# soc_aon_secure register map
Vendor: Texas Instruments
Registers are 32-bit, access per field, reset 0x0 unless marked. A register's access mark holds for its fields unless they carry their own. Offsets are as the file gives them; [hi:lo] are bit positions; {n}, {i} and the like mark numbered series; 'fields as' and 'values as' point back to an identical list.

## soc_aon_secure (part 3 of 3)
0x20D0 osprey_soc_aon_fuse_line1 ro — Fuse Line 1. Actual fuse line is 33.
  [31:0] UNQ31TO0 — Unique Device Identification [31:0]
0x20D4 osprey_soc_aon_fuse_line2 ro — Fuse Line 2. Actual fuse line is 34.
  [31:0] UNQ63TO32 — Unique Device Identification [63:32]
{0x20CC+4i} secgv_osprey_soc_aon_fuse_line{i} ro (i=3..6) — Fuse Line {i}. Actual fuse line is {i+32}.
  [31:0] UNQS{32i-65}TO{32i-96} — Unique Device Secret [{32i-65}:{32i-96}]
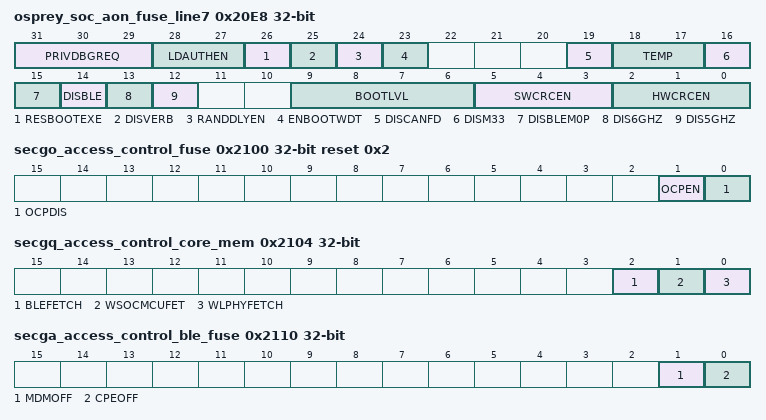
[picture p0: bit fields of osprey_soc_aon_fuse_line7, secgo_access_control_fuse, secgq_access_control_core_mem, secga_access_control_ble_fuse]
0x20E8 osprey_soc_aon_fuse_line7 ro — Fuse Line 7. Actual fuse line is 39.
  [31:29] PRIVDBGREQ — Enforce TI privilege Debug Request (Relevant in AT TEST privilege only used by SW) 0 - Disable other (1-7) - Enable (When SW check these bits: if equal to '0' bypass otherwise check.)
  [28:27] LDAUTHEN — RAM Bootloader authentication enable: 00 - Disable Other- Enable
  [26] RESBOOTEXE — Resume boot in non-normal boot flows where the boot cannot progress (e.g. when assets are hidden). For example, in forced supply in operational or deployed life cycles, 1st bday/at test (normal) life cycles, etc. 0 - Halt boot execution as early as possible 1 - Resume/Continue boot execution This bit is ignored when the device can run the boot flow normally (e.g. deployed life cycle with default SOP).
  [25] DISVERB — Disable Verbose Mode 0 - Verbose Mode (Enable) - Full Logger 1 - Normal Mode (Disable)
  [24] RANDDLYEN — Random Delay Enable: 0 - Disable 1 - Enable
  [23] ENBOOTWDT — Enable watchdog timer for protecting boot: (This enable M33 watchdog second threshold to reset device when asserted). 0 - Disable Boot Watchdog 1 - Enable Boot Watchdog
  [19] DISCANFD — Disable CAN FD - to eliminate the need to pay royalties 0 - Enable 1 - Disable (In probe we can program '0' (which practically means not programming) to achieve continuous programming it of all shifted rows) HCANEN (Enable/Disable the CAN IP) - Determined according to paper spin HCANRAMEN(Enable disable access to CAN memory) - Determined according to paper spin. HCANFDEN - Disable/Enable CAN. Determined according to eFuse bit (this bit)
  [18:17] TEMP — Supported Temperature 00 - 85degC 01 - 105degC 10 - 125degC 11 - Reserved
  [16] DISM33 — Disable M33 0 - Enable 1 - Disable (In probe we can program '0' (which practically means not programming) to achieve continuous programming it of all shifted rows)
  [15] DISBLEM0P — Disable BLE M0+ (RFC_CPE_CLKEN ) 0 - Enable 1 - Disable (In probe we can program '0' (which practically means not programming) to achieve continuous programming it of all shifted rows)
  [14] DISBLE — Disable BLE (RFC_MDM_CLKEN) 0 - Enable 1 - Disable (In probe we can program '0' (which practically means not programming) to achieve continuous programming it of all shifted rows)
  [13] DIS6GHZ — Disable 6GHz 0 - Enable 1 - Disable (In probe we can program '0' (which practically means not programming) to achieve continuous programming it of all shifted rows)
  [12] DIS5GHZ — Disable 5GHz 0 - Enable 1 - Disable (In probe we can program '0' (which practically means not programming) to achieve continuous programming it of all shifted rows)
  [9:6] BOOTLVL — Determine which part of the boot ROM bypass options for risk mitigation Level0 - Do not bypass anything Level1- Ignore Error Level2 - TI ROM bypass Level3 - Minimize access to HW. Do min mandatory. 0b0110 - Level3 0b1010 - Level 2 0b0101 - Level 1 All the rest - Level 0
  [5:3] SWCRCEN — SW CRC check Enable/Disable: 0 - Disable Other (1-7) - Enable (When SW check these bits: if equal to '0' do not check otherwise check.)
  [2:0] HWCRCEN — HW CRC check Enable/Disable: 0 - Disable other (1-7) - Enable (When HW check these bits: if equal to '0' do not check otherwise check.)
0x20EC osprey_soc_aon_fuse_line8 ro — Fuse Line 8. Actual fuse line is 40.
  [31:0] HWCRCVAL — HW CRC Check for all shifted rows. XORs operation with 0x04C11DB7 CRC32 polynomial engine. Init value = 0
0x2100 secgo_access_control_fuse reset 0x2 — Fuse Access Control. disconnect fuse from OCP access. locked with fuse_ocp_disable_lock.
  [1] OCPEN rw — OTP FROM , when jtag is 1 the i/f is jtag regardless of ocp_en to enable OCP need to write this bit to 1 and jtag to 0 '1' by default. optional - write once to '0'.
  [0] OCPDIS rw — Disconnect FUSE FARM and OTP OCP access, should be configured once as locked on boot done
0x2104 secgq_access_control_core_mem — CORE Memory Access Control CORE CPU: Allow M3 Fetch From non-owned memory Allow WiFi M0+ Fetch From non-owned memory Allow BLE M0+ Fetch From non-owned memory
  [2] BLEFETCH rw — Allow BLE M0+ Fetch From non-owned memory
  [1] WSOCMCUFET rw — Allow M3 Fetch From non-owned memory
  [0] WLPHYFETCH rw — Allow WiFi M0+ Fetch From non-owned memory
0x2108 secga_access_control_core_gp reset 0x1 — Access Control - Core Global Port Enable
  [0] ALLOW rw — Allow CORE global port. when enabled allow access to core (based on firewall configuration), must stay enabled to allow host access to Nub (sdio) and locked on soc_boot_done
0x210C secga_access_control_memss_gp reset 0x1 — MEMSS Global Port Access Control. Allow access to entire memss through memss global port.
  [0] ALLOW rw — Access is allowed to both M33 & M3 during privilege boot and changed to M3 only (fixed firewall) after boot (controlled by soc_boot_done)
0x2110 secga_access_control_ble_fuse — BLE Fuse Access Control. Disable BLE modem and CPE clock - based on indication bits on fuse
  [1] MDMOFF rw — Disable the BLE MDM clock , should be configured based on fuse pare spin
  [0] CPEOFF rw — This control disable the clk to the CPE clk gate. should be disabled in WIFI only paper spin (based on fuse)
0x2118 secgc_elevated_mode — not in use. can be use as spare
  [0] BIT rw — spare bit
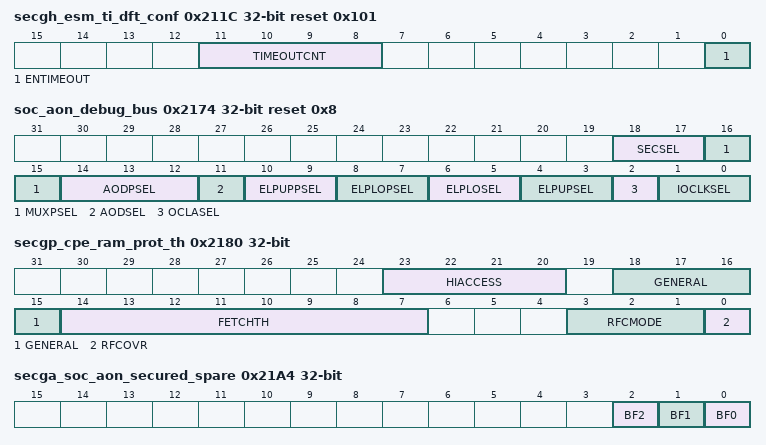
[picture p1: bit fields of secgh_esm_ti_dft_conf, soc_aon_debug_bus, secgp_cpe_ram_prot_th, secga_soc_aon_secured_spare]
0x211C secgh_esm_ti_dft_conf reset 0x101 — ESM4 Configuration- TI DFT Enable Sequence Monitor. Enable timeout mechanism and timeout counter value.
  [11:8] TIMEOUTCNT rw — This field sets the timeout value. time resolution equals to 16us. while: value 0 representing 16us value 1 - 2*16us value 2 - 3*16us and so on. value 15 is not supported.
  [0] ENTIMEOUT rw — This field enables timeout mechanism for ESM.
0x2120 ti_dft_en1 — ESM4 Enable Number 1.
  [0] EN1 wo — This field is the 1st enable for the ESM. Type: Write-Clear
0x2124 ti_dft_en2 — ESM4 Enable Number 2.
  [0] EN2 wo — This field is the 2nd enable for the ESM. Type: Write-Clear
0x2128 ti_dft_en3 — ESM4 Enable Number 3.
  [0] EN4 wo — This field is the 3rd enable for the ESM. Type: Write-Clear
0x212C ti_dft_en4 — ESM4 Enable Number 4.
  [0] EN4 wo — This field is the 4th enable for the ESM. Type: Write-Clear
0x2130 ti_dft_en5 — ESM4 Enable Number 5.
  [0] EN5 wo — This field is the 5th enable for the ESM. Type: Write-Clear
0x2140 secgb_socaon_access_protection access not given — This register is locking the CORE related security bits , should be written in boot and on elevated mode exit: [COREMEMCTL], [CRAMPROT1.FETCHTH], [DRAMPROT1.FETCHTH], [MEMPROT.MEMLOCK], [ROMJUMPCTL.DIS], [DRAMCTL.ERASEASST], [VTORCFG.INIT], [CPEPROT1.RFCOVR], [CPEPROT1.RFCMODE], [CPEPROT1.FETCHTH], [PHYPROT1.FETCHTH]
  [16] MEMLOCK — Locking the configurations on mem prot
0x2144 secgq_vtor — WSOC MCU VTOR CONFIGURATION. this is the jump address during boot (default is 0 - Rom) and after boot done - as POR this should be configured to CRAM start during boot of ROM. in boot done command the MCU will jump to this address
  [31:7] INIT rw — VTOR Init register
0x2148 secgc_mcu_rom_jumpdis — MCU ROM Jump Disable. Prevents the use of the VTOR function , by default it is off.
  [0] DIS rw — 0 - CTX icode bus jumps from 0x0/0x04 to vtor/vtor+4. 1 - Do not jump.
0x214C secgp_mcu_cram_prot_th — Execution RAM (CRAM) - Threshold register
  [15:7] WRTH rw — Below this CRAM Threshold register - Fetch/read only after 'mem_cram_write_disable_pulse'. Write is allowed above this threshold regardless to S/W setting the [CRAMPROT0.WRDIS]. Resolution is 1KB: (1- 1KB, 2 - 2KB, ..., 511 - 511KB). Effectively we have 384KB of Code-RAM
0x2150 mcu_cram_prot — Execution RAM (CRAM) - Protect from write
  [0] WRDIS wo — Write Once MMR protection - Do not allow writing to CRAM (below a threshold) after this MMR is set. S/W pulse (WRCL) that sets an H/W F.F - cannot be cleared by S/W.
0x2154 secgp_mcu_dram_prot_th — Execution RAM (CRAM) - Threshold register
  [14:7] FETCHTH rw — Below this DRAM Threshold register - read/write only (never-execute-region) after 'mem_dram_fetch_disable_pulse'. Fetch is allowed above this threshold regardless to S/W setting the [DRAMPROT0.FETCHDIS]. Resolution is 1KB: (1- 1KB, 2 - 2KB, ..., 255 - 255KB). Effectively we have 144KB of Data-RAM. [Cortex fetch from 61xx_xxxx (executable region) instead of 45xx_xxxx and the address is automatically (MCUSS H/W) remapped to 45xx_xxxx]
0x2158 mcu_dram_prot reset 0x200 (reset mask 0xFFFFFFFE) — Data RAM (DRAM) - Protect from fetch
  [0] FETCHDIS wo — Write Once MMR protection - Do not allow fetching from DRAM (below a threshold) after this MMR is set. S/W pulse (WRCL) that sets an H/W F.F - cannot be cleared by S/W.
0x2160 security_strong_pattern ro — Security Strong Pattern. the 24 bit pattern that is burn on the fuse to qualify the fuse data against possible attack
  [23:0] PAT — 24 bit pattern from fuse
0x2164 secgv_uds0 ro — Unique Device Secret. 31-0
  [31:0] _31TO0 — bits 31-0
{0x2164+4i} secgv_uds{i} ro (i=1..3) — Unique Device Secret. {32i+31}-{32i}
  [31:0] _{32i+31}TO{32i} — Bits {32i+31}-{32i}
0x2174 soc_aon_debug_bus reset 0x8 — SOC_AON Debug Bus. This register sets the debug over sleep and IOMUX debug bus selection
  [18:17] SECSEL rw — Security Debug Selector. selects soc aon debug bus
  [16:15] MUXPSEL rw — Debug Mux Port Selector. Chooses debug mux port '00' - prcm/elp '01' - soc aod '10' - ocla
  [14:12] AODPSEL rw — SOC AOD Port Selector. Chooses soc aod port '000' - host_aon_tp1 '001' - host_aon_tp2 '010' - io mux tp1 '011' - io mux tp2 '100' - debug aon tp1 '101' - debug aon tp2 '110' - soc aon tp1 '111' - rtc_tp1
  [11] AODSEL rw — SOC AOD Upper/Lower Selector. selects upper or lower 16 bits out of the soc aod bus of 32 '1' - 16 MSBs '0' - 16 LSBs
  [10:9] ELPUPPSEL rw — PRCM ELP Upper Port Selector. Chooses upper byte port '00' - prcm tp1 '01' - prcm tp2 '10' - elp tp1 '11' - elp tp2
  [8:7] ELPLOPSEL rw — PRCM ELP Lower Port Selector. Chooses lower byte port '00' - prcm tp1 '01' - prcm tp2 '10' - elp tp1 '11' - elp tp2
  [6:5] ELPLOSEL rw — PRCM ELP Lower Byte Selector. Chooses lower byte out of prcm elp 32 bit '00' - [7:0] '01' - [15:8] '10' - [23:16] '11' - [31:24]
  [4:3] ELPUPSEL rw — PRCM ELP Upper Byte Selector. Chooses upper byte out of prcm elp 32 bit '00' - [7:0] '01' - [15:8] '10' - [23:16] '11' - [31:24]
  [2] OCLASEL rw — OCLA bus upper/lower selector. selects upper or lower 16 bits out of the ocla bus of 32 '1' - 16 MSBs '0' - 16 LSBs
  [1:0] IOCLKSEL rw — selects the clock source for iomux debug clk 0 :SCLK 1: SOC CLK (40) 2: CORE M3 CLK (80)
0x217C debugss_jtagusercode rw — DEBUGSS JTAG User Code. This 32 bit register can be read through JTAG , and reflected on CFG-AP
  [31:0] JTAGUSER — This 32 bit register can be read through JTAG , and reflected on CFG-AP
0x2180 secgp_cpe_ram_prot_th reset not defined — Execution RAM (CRAM) - Threshold register
  [23:20] HIACCESS rw — Define the CPE (BLE CM0+) most high address space access allowed (should be configured according to MEM-SS mode). Value granularity is 16K, So for the default allocation of 64k it set to 3. (value 0 is for the lower 16k, value 15 is for 256k)
  [18:15] GENERAL rw — Bit 0 is force clk en for all BLE sub clocks . this is enabled on default for safety reasons on boot. this bit should be cleared by SW during boot and then internal IP clock manager takes control
  [14:7] FETCHTH rw — Above this BLE CPE Threshold register - read/write only (never-execute-region) after 'mem_dram_fetch_disable_pulse'. Fetch is allowed below this threshold regardless to S/W setting the [CPEPROT0.FETCHDIS]. Resolution is 1KB: (1- 1KB, 2 - 2KB, ..., 255 - 255KB). MSBit not in use (MSBit is reserved bit).
  [3:1] RFCMODE rw — RFC Confidential Mode.
  [0] RFCOVR rw — RFC Confidential Over.
0x2184 cpe_ram_prot reset 0x200 (reset mask 0xFFFFFFFE) — CPE Data RAM (DRAM) - Protect from fetch
  [0] FETCHDIS wo — Write Once MMR protection - Do not allow fetching from DRAM (above a threshold) after this MMR is set. S/W pulse (WRCL) that sets an H/W F.F - cannot be cleared by S/W.
0x2188 security_fuse_shift_crc ro — Security Fuse Shift CRC Calc result on fuse chain
  [31:0] CRCCALC — Calc CRC result of fuse chain - this include the CRC result crunching a s well, so expected / correct result would be 0.
0x218C security_hide_rom_assets — Security Hide Rom Assets. SW control to hide ROM assets, written once
  [0] HIDEASSETS wo — ROM is Hidden in case ATTEST or Error or if SOP=FS, during operational otherwise, during either Operational or ATTEST Privilege (except during privilege or elevated in which This MMR applies hide) Type: Write-Clear.
0x2190 security_hide_uds_assets — Security Hide UDS Assets. SW control to hide UDS assets, written once
  [0] HIDEASSETS wo — UDS is Hidden in case ATTEST or Error or.. during ATTEST-Privilege or Operational-and-not-in-force-supply-SOPs (except during soc privilege in which this MMR applies the hide) Type: Write-Clear.
0x2198 secgp_wlphy_ram_prot_th — WLPHY RAM memory protection - Threshold register
  [14:7] FETCHTH rw — Above this WLPHY Threshold register - read/write only (never-execute-region) after 'mem_wlphy_fetch_disable_pulse'. Fetch is allowed below this threshold regardless to S/W setting the [PHYPROT0.FETCHDIS]. Resolution is 1KB: (1- 1KB, 2 - 2KB, ..., 255 - 255KB). MSBit not in use. (MSBit is reserved bit)
0x219C wlphy_ram_prot reset 0x200 (reset mask 0xFFFFFFFE) — WLPHY RAM - Protect from fetch
  [0] FETCHDIS wo — Write Once MMR protection - Do not allow fetching from WLPHY RAM (above a threshold) after this MMR is set. S/W pulse (WRCL) that sets an H/W F.F - cannot be cleared by S/W.
0x21A0 esm_graceful_disable reset 0x200 (reset mask 0xFFFFFFFE) — ESMs Graceful Disable. Setting this bit - moving all ESM's from IDLE state to disabled state and cannot be configured until the next AON reset. notice this can be set only in IDLE mode - prior to other ESM configurations (i,e if ESM state is VIOLATED or DONE it will remain there)
  [0] DIS wo — Setting this bit - moving all ESM's from IDLE state to disabled state and cannot be configured until the next AON reset. notice this can be set only in IDLE mode - prior to other ESM configurations (i,e if ESM state is VIOLATED or DONE it will remain there)
0x21A4 secga_soc_aon_secured_spare — Spare bits , locked on boot
  [2] BF2 rw — Spare2 locked on boot done
  [1] BF1 rw — Spare1 locked on boot done
  [0] BF0 rw — Spare0 locked on boot done
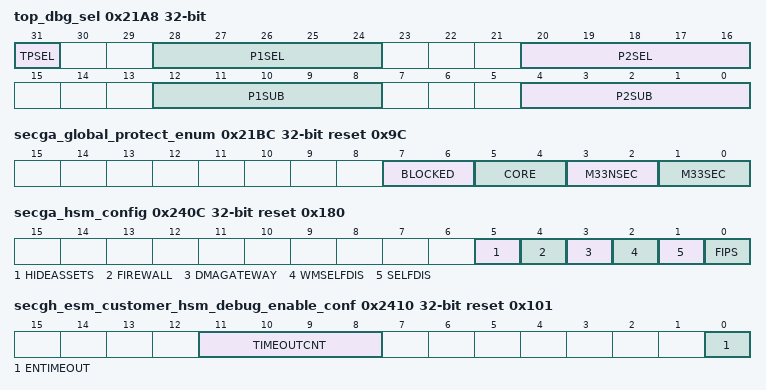
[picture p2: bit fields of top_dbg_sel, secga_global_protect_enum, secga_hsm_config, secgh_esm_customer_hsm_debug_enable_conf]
0x21A8 top_dbg_sel — Top Debug Selectors. This register selects debug ports from Top debug to OCLA. INTERNAL NOTE: [Confluence][https://confluence.itg.ti.com/display/WNG/Osprey+MDB+PG1.0+-+OCLA+integration+Spec] [LINUX- OSPREYMDB - MDBPG10C3V2 Branch][toplevel/wsoc/doc/wsoc.xls]
  [31] TPSEL rw — TP1/TP2 Selector. This field is used for Peripheral TP that have two 32bits TP (mode #3) e.g. SDIO_PHY, SDIO_FN1 In this case TP include 64 bits but we can expose only 32bits So we need this MMR field to select either TP1 or TP2 In this case this 16LSB(15:0) bit are connected to TP1 and 16MSB(31:16) to TP2 0 - Select IP TP1 1 - Select IP TP2 Example: TP1 = mem_ocla_tp1_tp2_sel ? IP_TP2[15: 0] : IP_TP1[15: 0] ; TP2 = mem_ocla_tp1_tp2_sel ? IP_TP2[31:16] : IP_TP1[31:16] ;
  [28:24] P1SEL rw — Port Set 1 - IP Selector. Selects the IP. INTERNAL NOTE- 2.2.4 SOC (TOP) [Confluence][https://confluence.itg.ti.com/display/WNG/Osprey+MDB+PG1.0+-+OCLA+integration+Spec]
  [20:16] P2SEL rw — Port Set 2 - IP Selector. Selects the IP. INTERNAL NOTE- 2.2.4 SOC (TOP) [Confluence][https://confluence.itg.ti.com/display/WNG/Osprey+MDB+PG1.0+-+OCLA+integration+Spec]
  [12:8] P1SUB rw — Port Set 1 - Submodule Selector. Selects the Submodule from the IP. INTERNAL NOTE- [LINUX- OSPREYMDB - MDBPG10C3V2 Branch][toplevel/wsoc/doc/wsoc.xls]
  [4:0] P2SUB rw — Port Set 2 - Submodule Selector. Selects the Submodule from the IP. INTERNAL NOTE- [LINUX- OSPREYMDB - MDBPG10C3V2 Branch][toplevel/wsoc/doc/wsoc.xls]
0x21BC secga_global_protect_enum reset 0x9C — Global Protect Enumeration. define of security group: [1:0] - M33 Secure [3:2] - M33 Non Secured [5:4] - Core [6:7] - Blocked
  [7:6] BLOCKED rw — BLOCKED Enumeration.
  [5:4] CORE rw — Core (M3) Enumeration.
  [3:2] M33NSEC rw — M33 Non-Secured Enumeration.
  [1:0] M33SEC rw — M33 Secured Enumeration.
{0x2370+0xC*i} doorbell{i}_m1_clr (i=0..7) — Doorbell {i} M3 Clear Register
  [0] CLR wo — M3 to clear the IRQ after handled the massage from M33. type : Write-Clear
0x2374 doorbell0_m1_pulse — Doorbell 0 M3 Set Register
  [0] IRQ wo — M3 to generate IRQ towards M33 after writing the message. type: Write-Clear
{0x2378+0xC*i} doorbell{i}_m1_lockbit (i=0..7) — Doorbell {i} M3 Lock Bit
  [1:0] LOCKBIT rw — Lock Bit. S/w attempt to lock upon read. if lock obtained, value set to 1 by h/w. M33 always looses to M3 Reading value: 00: not taken 01: taken by M3 (should wr IRQ afterwards) 10: taken by M33 11: invalid. generating the IRQ towards M33 clears the lock. Writing '00' also release the lock. 2'b10 means lock obtained by receiver side Type: Write-Read-Clear.
{0x2374+0xC*i} doorbell{i}_m1_pulse (i=1..7) — Doorbell {i} M3 Set Register
  [0] SET wo — M3 to generate IRQ towards M33 after writing the message. type: Write-Clear
0x23D0 m3_gpio_evt_sts_0 ro — M3 GPIO Event Status. 32 LSBs
  [31:0] STA31TO0 — 32 LSBs
0x23D4 m3_gpio_evt_sts_1 ro — M3 GPIO Event Status. 13 MSBs
  [12:0] STA44TO32 — 13 MSBs (44-32)
0x23E8 secgm_fuse_lock access not given — Fuse Lock. 1 lock. Write once. Issued to Fusefram Reg file and used to lock fusefarm OCP Disable indication (MMR), Locked immediately , cleared by core disable (or at soc aon reset or por reset)
  [0] OCPDIS — Locking the FUSE FARM OCP Reg File
0x23EC secgn_rom_boot_done access not given — ROM Boot Done. 1 lock. Write once. Asserted by FW at the end of ROM boot. Used to implement the ROM Hide, Locked immediately , cleared by core disable (or at soc aon reset or por reset)
  [0] DONE — Hiding the ROM at ROM Boot
0x23FC soc_boot_done access not given — SOC Boot Done. 1 lock. Write once. Asserted by FW at the end of TI secure boot, Used to lock the access to SOC security configurations , Locked immediately, cleared only at soc aon reset or por reset
  [0] DONE — locking the access to SOC security configurations
0x2400 elevated_done access not given — Elevated Mode Done. 1 lock. Write once. Asserted by FW at the end of elevated mode and indicates the end of elevated mode, Locked immediately , cleared by core disable (or at soc aon reset or por reset)
  [0] DONE — nd of elevated mode (M3 Boot ROM + M3 Core Boot)
0x2408 secgs_m3_tcm_access — M3 TCM Access. TCM access between M3 to M33
  [0] ACCESSDIS rw — M3 TCM Access Disable. Control the mux which select TCM access between M3 to M33 0. M3 1. M33
0x240C secga_hsm_config reset 0x180 (reset mask 0xFFFFFFC0) — HSM Configurations. Fips Support, HSM_Configs, HSM_assets_hide, hsm_controller_host_mode (or firewall_mode).
  [5] HIDEASSETS rw — HSM Assets Hide. Change the control on HSM assets from OCP to HSM. Controlling this value is allowed during boot (before soc_boot_done) is enabled
  [4] FIREWALL rw — HSM Firewall Mode. Select the controller id to hsm cpu_id transaction mode: 0-M3_MST_ID is translated to hsm cpu id 0 (controller host), this mode is used during boot (default=0) 1-M33_MST_ID (secure and non secure) are translated to hsm cpu id 0 (controller host), operational mode
  [3] DMAGATEWAY rw — DMA Gateway Mode. Define the ids to be used on hsm dma access to OCP: 0-M33 using HSM, use M33S and M33NS Mater IDs 1-M33+M3 are using the HSM, use M33S and M3 Mater IDs
  [2] WMSELFDIS rw — HSM Warmboot Post Disable. Disable self test & crc check on hsm reset exit, possible only is fips not supported: warmboot_post_disable: 0-enable self test on sleep exit, 1-disable self test on sleep exit (default=1)
  [1] SELFDIS rw — Disable self test & crc check on hsm reset exit, possible only is fips not supported: post_disable: 0-enable self test on reset exit, 1-disable self test on reset exit (default=1)
  [0] FIPS rw — Indication if hsm FIPS support: 1- HSM run in fips compliant mode 0- HSM doesn't run in fips compliant mode
0x2410 secgh_esm_customer_hsm_debug_enable_conf reset 0x101 — ESM4 Configuration- Customer HSM Debug Enable Sequence Monitor. Enable timeout mechanism and timeout counter value.
  fields as secgh_esm_ti_dft_conf
0x2414 customer_hsm_debug_enable_en1 — ESM5 Enable Number 1.
  fields as ti_dft_en1
0x2418 customer_hsm_debug_enable_en2 — ESM5 Enable Number 2.
  fields as ti_dft_en2
0x241C customer_hsm_debug_enable_en3 — ESM5 Enable Number 3.
  [0] EN3 wo — This field is the 3rd enable for the ESM. Type: Write-Clear
0x2420 customer_host_debug_enable_en4 — ESM5 Enable Number 4.
  [0] EN1 wo — This field is the 4th enable for the ESM. Type: Write-Clear
0x2424 customer_hsm_debug_enable_en5 — ESM5 Enable Number 5.
  fields as ti_dft_en5
0x2428 secgd_esm1_1st_magic_val — ESM1 1st Magic Value. This value is compared to hard coded value and unmask ESM only when value is matched. This additional compare allow ESM protection against fault injection
  [7:0] MGCVAL rw — ESM 1st magic value
0x242C secge_esm2_1st_magic_val — ESM2 1st Magic Value. This value is compared to hard coded value and unmask ESM only when value is matched. This additional compare allow ESM protection against fault injection
  [7:0] MGCVAL rw — ESM 1st magic value
0x2430 secgf_esm3_1st_magic_val — ESM3 1st Magic Value. This value is compared to hard coded value and unmask ESM only when value is matched. This additional compare allow ESM protection against fault injection
  [7:0] MGCVAL rw — ESM 1st magic value
0x2434 secgh_esm4_1st_magic_val — ESM4 1st Magic Value. This value is compared to hard coded value and unmask ESM only when value is matched. This additional compare allow ESM protection against fault injection
  [7:0] MGCVAL rw — ESM 1st magic value
0x2438 secgh_esm5_1st_magic_val — ESM5 1st Magic Value. This value is compared to hard coded value and unmask ESM only when value is matched. This additional compare allow ESM protection against fault injection
  [7:0] MGCVAL rw — ESM 1st magic value
0x2450 db_m3_imask reset 0xFFFF00 (reset mask 0xFFFFFF00) — M3 Doorbell IMASK. Mask Event. '0' - CLR - Clear Interrupt Mask '1' - SET - Set Interrupt Mask
  [7:0] IMASK rw — bit7 - doorbell 7 M3 IRQ bit6 - doorbell6 M3 IRQ bit5 - doorbell 5 M3 IRQ bit4 - doorbell 4 M3 IRQ bit3 - doorbell 3 M3 IRQ bit2 - doorbell 2 M3 IRQ bit1 - doorbell 1 M3 IRQ bit0 - doorbell 0 M3 IRQ
0x2454 db_m3_iset_evt_mng — M3 Doorbell ISET. Sets event in RIS Write 0 - NO_EFFECT - Writing 0 has no effect Write 1 - SET - Sets interrupt
  [7:0] ISET wo — bit7 - doorbell 7 M3 IRQ bit6 - doorbell6 M3 IRQ bit5 - doorbell 5 M3 IRQ bit4 - doorbell 4 M3 IRQ bit3 - doorbell 3 M3 IRQ bit2 - doorbell 2 M3 IRQ bit1 - doorbell 1 M3 IRQ bit0 - doorbell 0 M3 IRQ
0x2458 db_m3_iclr_evt_mng — M3 Doorbell ICLR. Clears event in RIS Write 0 - NO_EFFECT - Writing 0 has no effect Write 1 - CLR - Clears the Event
  [7:0] ICLR wo — bit7 - doorbell 7 M3 IRQ bit6 - doorbell6 M3 IRQ bit5 - doorbell 5 M3 IRQ bit4 - doorbell 4 M3 IRQ bit3 - doorbell 3 M3 IRQ bit2 - doorbell 2 M3 IRQ bit1 - doorbell 1 M3 IRQ bit0 - doorbell 0 M3 IRQ
0x245C db_m3_imset_evt_mng — M3 Doorbell IMSET. Sets Event Write 0 - NO_EFFECT - Writing 0 has no effect Write 1 - SET - Set interrupt mask
  [7:0] IMSET wo — bit7 - doorbell 7 M3 IRQ bit6 - doorbell6 M3 IRQ bit5 - doorbell 5 M3 IRQ bit4 - doorbell 4 M3 IRQ bit3 - doorbell 3 M3 IRQ bit2 - doorbell 2 M3 IRQ bit1 - doorbell 1 M3 IRQ bit0 - doorbell 0 M3 IRQ
0x2460 db_m3_imclr_evt_mng — M3 Doorbell IMCLR. Clears Event Write 0 - NO_EFFECT - Writing 0 has no effect Write 1 - CLR - Clear interrupt mask
  [7:0] IMCLR wo — bit7 - doorbell 7 M3 IRQ bit6 - doorbell6 M3 IRQ bit5 - doorbell 5 M3 IRQ bit4 - doorbell 4 M3 IRQ bit3 - doorbell 3 M3 IRQ bit2 - doorbell 2 M3 IRQ bit1 - doorbell 1 M3 IRQ bit0 - doorbell 0 M3 IRQ
0x2464 db_m3_ris_evt_mng ro — M3 Doorbell RIS. Raw interrupt status for event. This bit is set to 1 when an event is received. when the corresponding bit in ICLR is set to 1, this bit will be cleared. Read 0 - CLR - Interrupt did not occur Read 1 - SET - Interrupt occurred
  [7:0] RIS — bit7 - doorbell 7 M3 IRQ bit6 - doorbell6 M3 IRQ bit5 - doorbell 5 M3 IRQ bit4 - doorbell 4 M3 IRQ bit3 - doorbell 3 M3 IRQ bit2 - doorbell 2 M3 IRQ bit1 - doorbell 1 M3 IRQ bit0 - doorbell 0 M3 IRQ
0x2468 db_m3_mis_evt_mng ro — M3 Doorbell MIS. Mask interrupt status for event Read 0 - CLR - Interrupt did not occur Read 1 - SET - Interrupt occurred
  [7:0] MIS — bit7 - doorbell 7 M3 IRQ bit6 - doorbell6 M3 IRQ bit5 - doorbell 5 M3 IRQ bit4 - doorbell 4 M3 IRQ bit3 - doorbell 3 M3 IRQ bit2 - doorbell 2 M3 IRQ bit1 - doorbell 1 M3 IRQ bit0 - doorbell 0 M3 IRQ
0x2680 secga_host_crtx_sys_reset_request — M33 cortex system reset request
  [0] SYSRSTREQ rw — M33 cortex system reset request. Level register. 1 - request for reset 0- lower reset request User should set and clear this register (two writes)
0x2684 secga_firewall_config_soc_bypass reset 0x1 — SOC Firewall Bypass
  [0] BYPASS rw
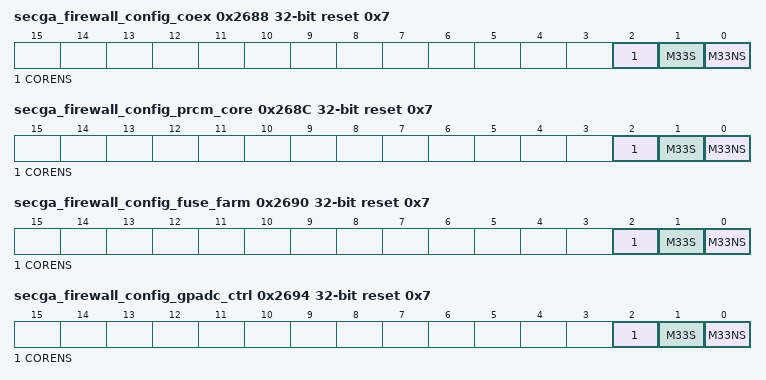
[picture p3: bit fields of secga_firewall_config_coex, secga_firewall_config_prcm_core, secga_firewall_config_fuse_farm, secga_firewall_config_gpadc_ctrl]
0x2688 secga_firewall_config_coex reset 0x7 — COEX firewall access permission for 3 controller id : 0 - M33 Non Secured 1 - M33 Secured 2 - Core (Non Secure)
  [2] CORENS rw — Controller Core Non Secured: '0' - access not allowed '1' - access allowed
  [1] M33S rw — Controller M33 Secured: '0' - access not allowed '1' - access allowed
  [0] M33NS rw — Controller M33 None Secured: '0' - access not allowed '1' - access allowed
0x268C secga_firewall_config_prcm_core reset 0x7 — PRCM CORE + M3 Scratchpad firewall access permission for 3 controller id : 0 - M33 Non Secured 1 - M33 Secured 2 - Core (Non Secure)
  fields as secga_firewall_config_coex
0x2690 secga_firewall_config_fuse_farm reset 0x7 — FUSE FARM firewall access permission for 3 controller id : 0 - M33 Non Secured (valid only in privilege mode) 1 - M33 Secured (valid only in privilege mode) 2 - Core (Non Secure)
  [2] CORENS rw — Controller Core Non Secured: '0' - access not allowed '1' - access allowed
  [1] M33S rw — Controller M33 Secured: '0' - access not allowed '1' - access allowed
  [0] M33NS rw — Controller M33 None Secured: Controller M33 None Secured: '0' - access not allowed '1' - access allowed
0x2694 secga_firewall_config_gpadc_ctrl reset 0x7 — GPADC firewall access permission for 3 controller id : 0 - M33 Non Secured 1 - M33 Secured 2 - Core (Non Secure)
  fields as secga_firewall_config_coex
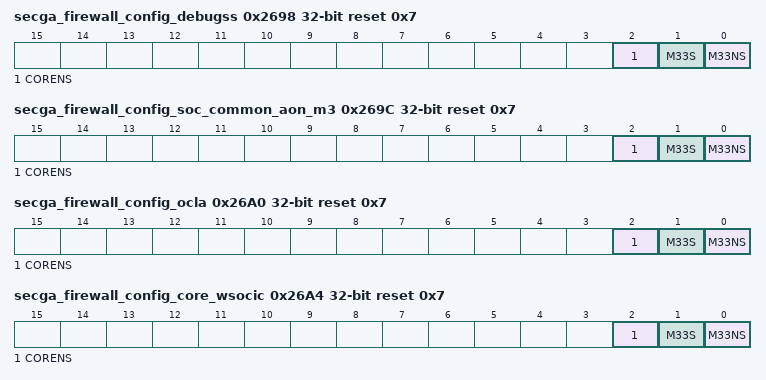
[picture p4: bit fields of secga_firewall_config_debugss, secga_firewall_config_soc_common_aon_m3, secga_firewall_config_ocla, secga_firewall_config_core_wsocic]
0x2698 secga_firewall_config_debugss reset 0x7 — DEBUGSS firewall access permission for 3 controller id : 0 - M33 Non Secured 1 - M33 Secured 2 - Core (Non Secure)
  fields as secga_firewall_config_coex
0x269C secga_firewall_config_soc_common_aon_m3 reset 0x7 — SOC_AON_M3 firewall access permission for 3 controller id : 0 - M33 Non Secured 1 - M33 Secured 2 - Core (Non Secure)
  fields as secga_firewall_config_coex
0x26A0 secga_firewall_config_ocla reset 0x7 — OCLA firewall access permission for 3 controller id : 0 - M33 Non Secured 1 - M33 Secured 2 - Core (Non Secure)
  fields as secga_firewall_config_coex
0x26A4 secga_firewall_config_core_wsocic reset 0x7 — WSOC_IC firewall access permission for 3 controller id : 0 - M33 Non Secured 1 - M33 Secured 2 - Core (Non Secure)
  fields as secga_firewall_config_coex
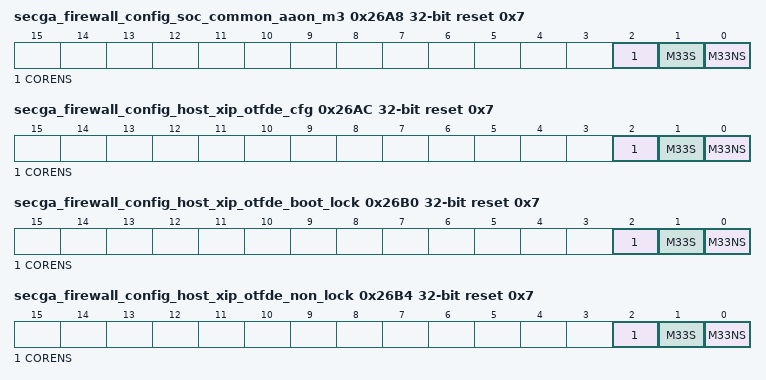
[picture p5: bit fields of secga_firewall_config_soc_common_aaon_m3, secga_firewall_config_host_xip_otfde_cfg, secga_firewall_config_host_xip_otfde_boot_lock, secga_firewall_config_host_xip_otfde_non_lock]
0x26A8 secga_firewall_config_soc_common_aaon_m3 reset 0x7 — SOC_AAON_M3 firewall access permission for 3 controller id : 0 - M33 Non Secured 1 - M33 Secured 2 - Core (Non Secure)
  fields as secga_firewall_config_coex
0x26AC secga_firewall_config_host_xip_otfde_cfg reset 0x7 — XIP_CFG firewall access permission for 3 controller id : 0 - M33 Non Secured 1 - M33 Secured 2 - Core (Non Secure)
  fields as secga_firewall_config_coex
0x26B0 secga_firewall_config_host_xip_otfde_boot_lock reset 0x7 — OTFE_BOOT_LOCK firewall access permission for 3 controller id : 0 - M33 Non Secured 1 - M33 Secured 2 - Core (Non Secure)
  fields as secga_firewall_config_coex
0x26B4 secga_firewall_config_host_xip_otfde_non_lock reset 0x7 — OTFDE_NON_LOCK firewall access permission for 3 controller id : 0 - M33 Non Secured 1 - M33 Secured 2 - Core (Non Secure)
  fields as secga_firewall_config_coex
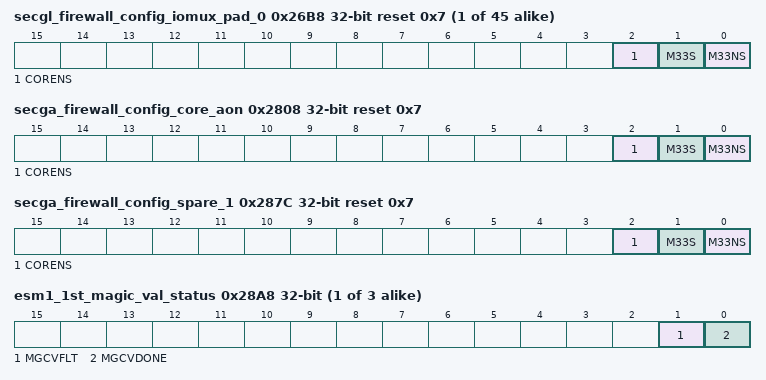
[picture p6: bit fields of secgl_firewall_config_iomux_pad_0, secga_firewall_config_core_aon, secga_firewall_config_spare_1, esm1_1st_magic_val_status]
{0x26B8+4i} secgl_firewall_config_iomux_pad_{i} reset 0x7 (i=0..44) — IOMUX_PAD_{i} firewall access permission for 3 controller id : 0 - M33 Non Secured 1 - M33 Secured 2 - Core (Non Secure)
  fields as secga_firewall_config_coex
0x2808 secga_firewall_config_core_aon reset 0x7 — CORE_AON firewall access permission for 3 controller id : 0 - M33 Non Secured 1 - M33 Secured 2 - Core (Non Secure)
  fields as secga_firewall_config_coex
0x287C secga_firewall_config_spare_1 reset 0x7 — Spare firewall access register. locked by SOC BOOT DONE (secgk) 3 access bits - {M33NS , M33S , M3} .
  fields as secga_firewall_config_coex
0x2898 secgb_boot_status rw — Boot Status. Report boot status which reflected on Config AP on DebugSS and can be read by JTAG (tools), these configuration will be used by both privilege and elevated boot code The Boot status reveal is controlled by FW - status will be updated using authenticated request.
  [31:0] BOOTSTA — Boot Status.
0x289C secgb_lifecycle_config — LifeCycle Config. Report device parameters to config - AP.
  [31:8] DEVPARAMS rw — Bits 7:0 - Fixed lifecycle taken from HW (SW_LIFECYCLE, HW_LIFECYCLE) Bits 31:8 - device parameters (fuse/SW)
0x28A0 esm1_status ro — status register , for each of the ESM (enable sequence monitor) what is the current state of esm.
  [3:0] STATE — 5 states: 0000 - READY 0001 - ENABLED (not guarenteed that magic values match) 0010 - PENDING TO NEXT WRITE 0100 - GRACFULLY LOCKED 1000 - FAULT
0x28A4 esm2_status ro — status register , for each of the ESM (enable sequence monitor) what is the current state of esm.
  fields as esm1_status
{0x28A4+4i} esm{i}_1st_magic_val_status ro (i=1..3) — ESM{i} 1st magic value match indication.
  [1] MGCVFLT — ESM 1st magic val fault ( note: indicates fault before a write to the magic val register)
  [0] MGCVDONE — ESM 1st magic val match
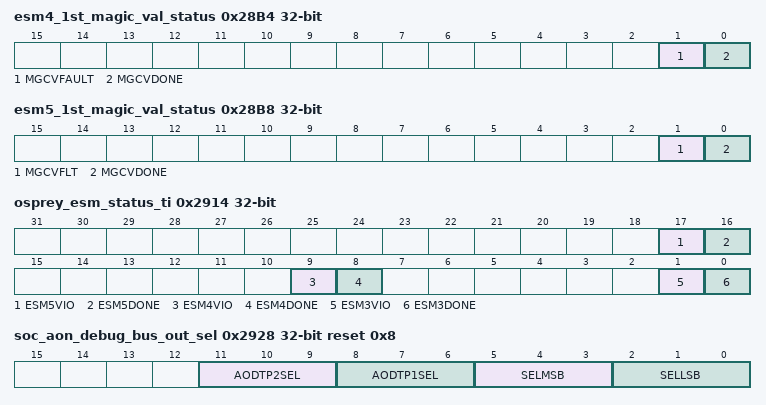
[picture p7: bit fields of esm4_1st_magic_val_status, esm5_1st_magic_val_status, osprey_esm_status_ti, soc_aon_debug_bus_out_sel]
0x28B4 esm4_1st_magic_val_status ro — ESM4 1st magic value match indication.
  [1] MGCVFAULT — ESM 1st magic val fault ( note: indicates fault before a write to the magic val register)
  [0] MGCVDONE — ESM 1st magic val match
0x28B8 esm5_1st_magic_val_status ro — ESM5 1st magic value match indication.
  fields as esm1_1st_magic_val_status
0x2908 enable_secg_serror — Enable Security Group SERROR. Enable SERROR when trying to access locked register in SOC AON , HOSTXIP and WSOCCOMMONS regfiles
  [0] EN rw — Enable secgroup serror.
0x290C secga_erase_assets_dram reset 0x200 (reset mask 0xFFFFFFFE) — Erase Assets DRAM.
  [0] ERASEASST rw — Enable the automatic erase of the assets area of DRAM (8K) upon core reset exit. This action erase 8k in 25.6us
0x2910 conn_stop_ctl_by_m33 access not given reset 0x200 (reset mask 0xFFFFFFFE) — Conn Stop Control By M33. '1' - Switch control of con_stop from HW (default con start) to M33 (default con stop)
  [0] SWITCH — '1' - Switch control of con_stop from HW (default con start) to M33 (default con stop)
0x2914 osprey_esm_status_ti ro — TI ESMs STATUS (3,4,5) status register , for each of the ESM (enable sequence monitor) what is the status (Done, violated, or None). Final ESM status for the entire ESM - ESM machine + magic value comparators
  [17] ESM5VIO — ESM 5 Violated.
  [16] ESM5DONE
  [9] ESM4VIO — ESM 4 Violated.
  [8] ESM4DONE
  [1] ESM3VIO — ESM 3 Violated.
  [0] ESM3DONE
0x2918 m3_gpio_mis_0 ro — M3 GPIO Functional MIS. 32 LSBs
  [31:0] _31TO0
0x291C m3_gpio_mis_1 ro — M3 GPIO Functional MIS. 13 MSBs (44-32)
  [12:0] _44TO32
0x2920 m3_gpio_func_0 rw — M3 GPIO Functional Mask
  [31:0] MASK31TO0 — M3 GPIO Functional Mask. 32 LSBs 0. Mask 1. Un-Mask
0x2924 m3_gpio_func_1 — M3 GPIO Functional Mask
  [12:0] MASK44TO32 rw — M3 GPIO Functional Mask. 13 MSBs (44-32) 0. Mask 1. Un-Mask
0x2928 soc_aon_debug_bus_out_sel reset 0x8 — Debug Bus Out Select. This register sets the debug over sleep and IOMUX debug bus selection
  [11:9] AODTP2SEL rw — AOD to OCLA TP2 Select. Chooses debug mux port to ocla '000' - prcm tp2 '001' - elp tp2 '010' - rtc tp2 '011' - iomux tp2 '100' - debug aon tp2 '101' - soc aon tp1 '110' - host aon tp2
  [8:6] AODTP1SEL rw — AOD to OCLA TP1 select. Chooses debug mux port to ocla '000' - prcm tp1 '001' - elp tp1 '010' - rtc tp1 '011' - iomux tp1 '100' - debug aon tp1 '101' - soc aon tp1 '110' - host aon tp1
  [5:3] SELMSB rw — Debug mux port select MSB: Chooses debug mux port to iomux '000' - prcm/elp debug mux [7:0] '001' - prcm/elp debug mux [15:8] '010' - soc aod debug mux [7:0] '011' - soc aod debug mux [15:8] '100' - ocla debug mux [7:0] '101' - ocla debug mux [15:8]
  [2:0] SELLSB rw — Debug mux port select LSB: Chooses debug mux port to iomux '000' - prcm/elp debug mux [7:0] '001' - prcm/elp debug mux [15:8] '010' - soc aod debug mux [7:0] '011' - soc aod debug mux [15:8] '100' - ocla debug mux [7:0] '101' - ocla debug mux [15:8]
0x292C m33_cpuwait access not given — M33 CPUWAIT. lock once. Do Not lock until written. When written Locked immediately, cleared only at soc aon reset or por reset. These are host security lock configurations
  [0] EXIT — locking HOSTMCU CPUWAIT '1' - use FSM value '0' - CPUWAIT
0x2930 m3_spare — spare reg for m3 aperture. not locked.
  [3:0] BF rw — M3 spare register
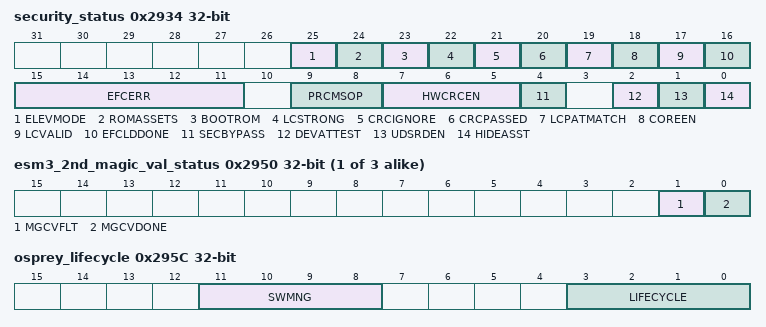
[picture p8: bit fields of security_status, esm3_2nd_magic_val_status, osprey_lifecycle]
0x2934 security_status ro — Security AON Status.
  [25] ELEVMODE — Device Elevated Mode.
  [24] ROMASSETS — Hide Rom Assets, 0 - OPEN 1- HIDE This bit is the status of ROM hide H/W indication. 1 - ROM Assets (2KB in M3 BOOT ROM is hidden); 0 - ROM Assets (2KB in M3 BOOT ROM) is NOT hidden. NOTE: same as [HIDEASSETS]
  [23] BOOTROM — Hide Boot ROM. This bit is the status of ROM hide H/W indication. 1 - entire ROM is hidden; 0 - ROM Assets is NOT hidden.
  [22] LCSTRONG — Device LifeCycle Strong Pattern Valid. 0 - FAIL 1- PASS This bit indicates the fuse shift is done without EFC error
  [21] CRCIGNORE — PRCM Ignore Fuse CRC Check. 0 - NO 1 - YES This bit indicates the Device System PRCM module sets the CRC check ignored bit
  [20] CRCPASSED — Fuse CRC Check Passed. 0 - NO 1- YES This bit indicates the Device h/w fuse shift has passed without CRC error, or that fuse shift is done with the CRC check being ignored by System PRCM module
  [19] LCPATMATCH — Pattern Match LyfeCycle. 0 - NO_MATCH 1 - MATCH This bit indicates the Device h/w fuse shift has done and that the Lifecycle matches the strong pattern. Meaning pattern equal to 0 in LC equal to 0 or 1; pattern equal to LC of ATTST PRIVILEGE; pattern equal to LC of Operational; NOTE: No validity Check is conditioning this indication. Specifically no EFC or CRC check masks this indication.
  [18] COREEN — Core Enable, 0 - NO 1 - YES This bit indicates the Device Application CPU requested the Network CPU to power off ("Connectivity Stop" a.k.a "SL STOP" in former device family). When This bit is set the Network Core CPU registers will be automatically cleared. The device is now ready to be reloaded in "elevated mode" namely Secondary Boot.
  [17] LCVALID — Device LifeCycle Valid. 0 - FAIL 1 - PASS This bit indicates the Device h/w fuse shift has pass without EFC or CRC errors and that the Lifecycle matches the strong pattern. Meaning pattern equal to 0 in LC equal to 0 or 1; pattern equal to LC of ATTST PRIVILEGE; pattern equal to LC of Operational;
  [16] EFCLDDONE — EFC Autoload Done. 0 - FAIL 1 - PASS This bit indicates the Device h/w fuse shit progress has been done.
  [15:11] EFCERR — EFC Error. This field reflects the Device fuse shift EFC error 5 bits. All zeros means no error.
  [9:8] PRCMSOP — PRCM SOP: 0- DEBUG 1- DEFAULT 2- FSPKG 3- FSPRB This field reflects the Device Sense on Power (SOP): OSPREY_DEV_SOP_SOC_DEBUG 2'h0 OSPREY_DEV_SOP_DEFAULT 2'h1 OSPREY_DEV_SOP_FORCE_SUPPLY_PKG 2'h2 OSPREY_DEV_SOP_FORCE_SUPPLY 2'h3
  [7:5] HWCRCEN — HW CRC Enable. This field reflects the Device fuse shift field HWCRCEN (3b) in case that EFC check has passed. Otherwise, it reflects "000"
  [4] SECBYPASS — Security Bypass. 0 - FALSE 1 - TRUE This bit indicates the Device is in ATTEST (or First Birthday). Specifically, the Fuse pass without EFC or CRC errors, the Lifecycle is either 0 or 1 and strong pattern is all zeros. NOTE: same as [DEVATTEST]
  [2] DEVATTEST — Device At test. 0 - FALSE 1 - TRUE This bit indicates the Device is in ATTEST (or First Birthday). Specifically, the Fuse pass without EFC or CRC errors, the Lifecycle is either 0 or 1 and strong pattern is all zeros. NOTE: same as [SECBYPASS]
  [1] UDSRDEN — UDS Read Enable. 0 - HIDE 1- OPEN This bit is the status of UDS hide H/W indication. 1 - UDS is readable; 0 - UDS is hidden. The Status Registers [UDS0.*], [UDS1.*], [UDS2.*], [UDS3.*] and [FUSELINE3.*], [FUSELINE4.*], [FUSELINE5.*], [FUSELINE6.*] will be read as 0
  [0] HIDEASST — Hide assets. 0. OPEN 1. HIDE This bit is the status of ROM hide H/W indication. 1 - ROM Assets (2KB in M3 BOOT ROM is hidden); 0 - ROM Assets (2KB in M3 BOOT ROM) is NOT hidden. NOTE: same as [ROMASSETS]
0x2938 secgf_esm3_2nd_magic_val — ESM3 2nd Magic Value. This value is compared to hard coded value and unmask ESM only when value is matched. This additional compare allow additional protection on ESM and also allow vendor to unmask ESM only at the end of vendor secure boot (SBL) is completed
  [7:0] MGCVAL rw — ESM 2nd magic value
0x293C secgh_esm4_2nd_magic_val — ESM4 2nd Magic Value. This value is compared to hard coded value and unmask ESM only when value is matched. This additional compare allow additional protection on ESM and also allow vendor to unmask ESM only at the end of vendor secure boot (SBL) is completed
  [7:0] MGCVAL rw — ESM 2nd magic value
0x2940 secgh_esm5_2nd_magic_val — ESM5 2nd Magic Value. This value is compared to hard coded value and unmask ESM only when value is matched. This additional compare allow additional protection on ESM and also allow vendor to unmask ESM only at the end of vendor secure boot (SBL) is completed
  [7:0] MGCVAL rw — ESM 2nd magic value
{0x2938+4i} esm{i}_status ro (i=3..5) — ESM{i} Status. status register , for each of the ESM (enable sequence monitor) what is the current state of esm.
  fields as esm1_status
{0x2944+4i} esm{i}_2nd_magic_val_status ro (i=3..5) — ESM{i} 2nd magic value match indication.
  [1] MGCVFLT — ESM 2nd magic val fault ( note: indicates fault before a write to the magic val register)
  [0] MGCVDONE — ESM 2nd magic val match
0x295C osprey_lifecycle ro — This register contains information on Device Life Cycles ad follow: 1. [11:8] Device Life Cycle SW Managed - as exist at [FUSELINE0.DEVLCSW] 2. [3:0] Device Life Cycle - based on Device Life Cycle HW Managed as exist at [FUSELINE0.DEVLCHW] but with following decoding and validation logic: if fuse data is valid- no crc/no efc ready /pattern error the Decoded value is: 0 - 1st Birthday 1 - AT TEST 2 - AT TEST Privilege 3 - Operational otherwise, the value is 4 - fault mode -fault occurred on life cycle read
  [11:8] SWMNG — OSPREY SW device lifecycle
  [3:0] LIFECYCLE — OSPREY device lifecycle
